# COMPUTE_CLUSTER0_DRU_FW register map
Vendor: Texas Instruments
Peripheral module from a debugger description file (folder am65x).
Registers are 32-bit, read-write, reset 0x0 unless marked. A register's access mark holds for its fields unless they carry their own. Offsets are as the file gives them; lines under a group give offsets from that group; [hi:lo] are bit positions; {n}, {i} and the like mark numbered series; 'fields as' and 'values as' point back to an identical list; <NAME> marks a mode.

## COMPUTE_CLUSTER0_DRU_FW
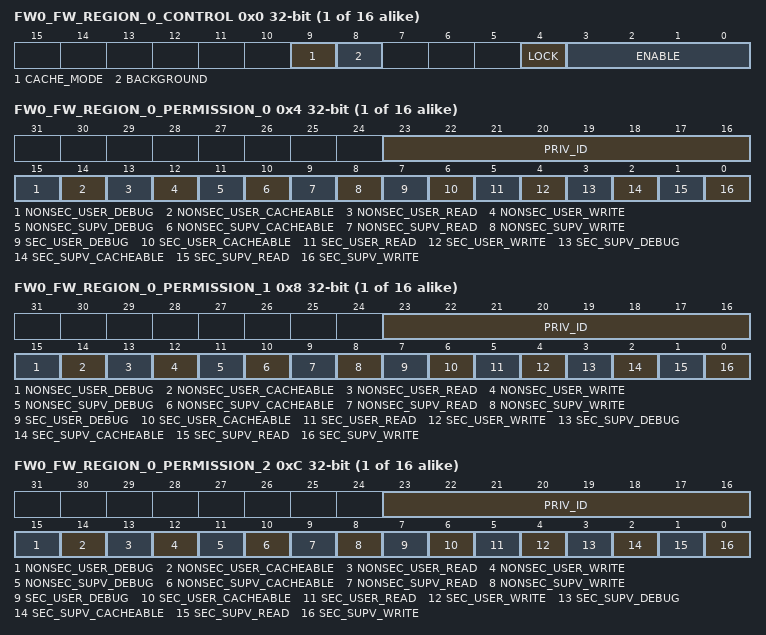
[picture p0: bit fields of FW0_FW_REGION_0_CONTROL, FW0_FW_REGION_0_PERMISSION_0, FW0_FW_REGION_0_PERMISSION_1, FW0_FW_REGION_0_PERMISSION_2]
{0x0+0x20*i} FW0_FW_REGION_{i}_CONTROL (i=0..15) — The FW Region {i} Control Register defines the control fields for the slave fw0 region {i} firewall.
  [9] CACHE_MODE — Cache mode for region.Set to 1 to check cache permissions. Set to 0 to ignore cache permissions.
  [8] BACKGROUND — Background enable for region.There can be 1 backgroun region per FW and foreground regions can have overlapping addresses only with the background region.
  [4] LOCK — Lock region.Once set region values cannot be modified.
  [3:0] ENABLE — Enable region.A value of 0xA enables, others disable.
{0x4+0x20*i} FW0_FW_REGION_{i}_PERMISSION_0 (i=0..15) — The FW Region {i} Permission 0 Register defines the permissions for the slave fw0 region {i} firewall.
  [23:16] PRIV_ID — Allowed privid.
  [15] NONSEC_USER_DEBUG — Non-secure user debug allowed.
  [14] NONSEC_USER_CACHEABLE — Non-secure user cacheable allowed.
  [13] NONSEC_USER_READ — Non-secure user read allowed.
  [12] NONSEC_USER_WRITE — Non-secure user write allowed.
  [11] NONSEC_SUPV_DEBUG — Non-secure supervisor debug allowed.
  [10] NONSEC_SUPV_CACHEABLE — Non-secure supervisor cacheable allowed.
  [9] NONSEC_SUPV_READ — Non-secure supervisor read allowed.
  [8] NONSEC_SUPV_WRITE — Non-secure supervisor write allowed.
  [7] SEC_USER_DEBUG — Secure user debug allowed.
  [6] SEC_USER_CACHEABLE — Secure user cacheable allowed.
  [5] SEC_USER_READ — Secure user read allowed.
  [4] SEC_USER_WRITE — Secure user write allowed.
  [3] SEC_SUPV_DEBUG — Secure supervisor debug allowed.
  [2] SEC_SUPV_CACHEABLE — Secure supervisor cacheable allowed.
  [1] SEC_SUPV_READ — Secure supervisor read allowed.
  [0] SEC_SUPV_WRITE — Secure supervisor write allowed.
{0x8+0x20*i} FW0_FW_REGION_{i}_PERMISSION_1 (i=0..15) — The FW Region {i} Permission 1 Register defines the permissions for the slave fw0 region {i} firewall.
  fields as FW0_FW_REGION_0_PERMISSION_0
{0xC+0x20*i} FW0_FW_REGION_{i}_PERMISSION_2 (i=0..15) — The FW Region {i} Permission 2 Register defines the permissions for the slave fw0 region {i} firewall.
  fields as FW0_FW_REGION_0_PERMISSION_0
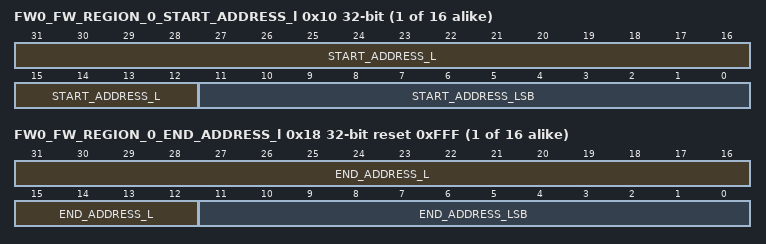
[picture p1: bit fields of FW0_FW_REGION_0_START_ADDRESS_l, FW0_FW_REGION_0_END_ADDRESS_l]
{0x10+0x20*i} FW0_FW_REGION_{i}_START_ADDRESS_l access per field (i=0..15) — The FW Region {i} Start Address Low Register defines the start address bits 31 to 0 for the slave fw0 region {i} firewall.
  [31:12] START_ADDRESS_L rw — Start address bits 31 to 12.Lowest 12 bits are forced to 0 as address must be 4KB aligned.
  [11:0] START_ADDRESS_LSB ro — Start address bits 11 to 0 are forced to 0 as address must be 4KB aligned.
{0x14+0x20*i} FW0_FW_REGION_{i}_START_ADDRESS_H (i=0..15) — The FW Region {i} Start Address High Register defines the start address bits 47 to 32 for the slave fw0 region {i} firewall.
  [15:0] START_ADDRESS_H — Start address bits 47 to 32.
{0x18+0x20*i} FW0_FW_REGION_{i}_END_ADDRESS_l access per field reset 0xFFF (i=0..15) — The FW Region {i} End Address Low Register defines the end address bits 31 to 0 to include for the slave fw0 region {i} firewall.
  [31:12] END_ADDRESS_L rw — End address bits 31 to 12 to include in the match.Lowest 12 bits are forced to 1s as address must be 4KB aligned.
  [11:0] END_ADDRESS_LSB ro — End address bits 11 to 0 are forced to 1s as address must be 4KB aligned minus 1.
{0x1C+0x20*i} FW0_FW_REGION_{i}_END_ADDRESS_H (i=0..15) — The FW Region {i} End Address High Register defines the end address bits 47 to 32 to include for the slave fw0 region {i} firewall.
  [15:0] END_ADDRESS_H — End address bits 47 to 32 to include in the match.
